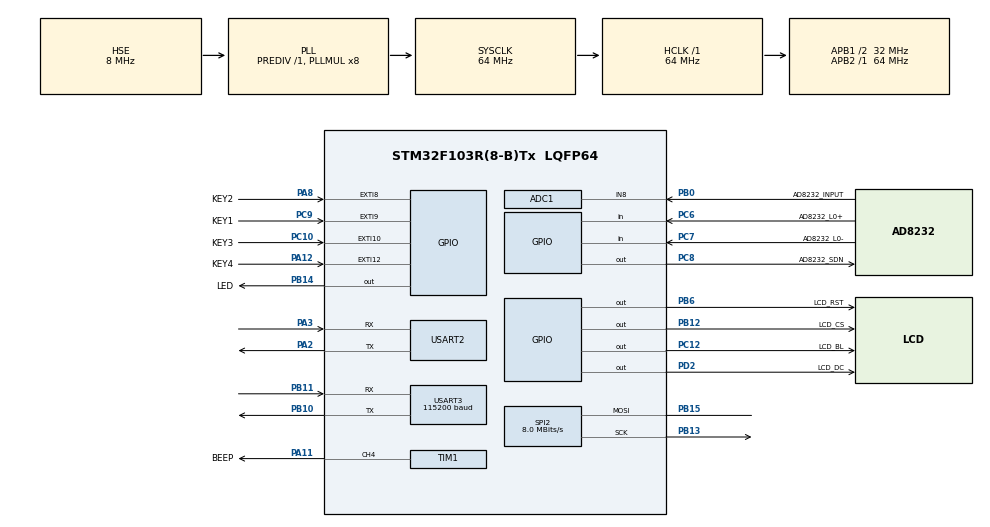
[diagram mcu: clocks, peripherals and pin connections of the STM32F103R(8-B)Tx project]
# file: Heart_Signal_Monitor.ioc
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ADC1.Channel-1\#ChannelRegularConversion=ADC_CHANNEL_8
ADC1.ExternalTrigConv=ADC_EXTERNALTRIGCONV_T3_TRGO
ADC1.NbrOfConversionFlag=1
ADC1.Rank-1\#ChannelRegularConversion=1
ADC1.SamplingTime-1\#ChannelRegularConversion=ADC_SAMPLETIME_55CYCLES_5
ADC1.master=1
Dma.ADC1.0.Direction=DMA_PERIPH_TO_MEMORY
Dma.ADC1.0.Instance=DMA1_Channel1
Dma.ADC1.0.MemDataAlignment=DMA_MDATAALIGN_HALFWORD
Dma.ADC1.0.MemInc=DMA_MINC_ENABLE
Dma.ADC1.0.Mode=DMA_CIRCULAR
Dma.ADC1.0.PeriphDataAlignment=DMA_PDATAALIGN_HALFWORD
Dma.ADC1.0.PeriphInc=DMA_PINC_DISABLE
Dma.ADC1.0.Priority=DMA_PRIORITY_VERY_HIGH
Dma.Request0=ADC1
Mcu.Family=STM32F1
Mcu.Name=STM32F103R(8-B)Tx
Mcu.Package=LQFP64
NVIC.DMA1_Channel1_IRQn=true\:0\:0\:false\:false\:true\:false\:true\:true
NVIC.EXTI15_10_IRQn=true\:0\:0\:false\:false\:true\:true\:true\:true
NVIC.EXTI9_5_IRQn=true\:0\:0\:false\:false\:true\:true\:true\:true
NVIC.PriorityGroup=NVIC_PRIORITYGROUP_4
NVIC.TIM1_BRK_IRQn=true\:0\:0\:false\:false\:true\:true\:true\:true
NVIC.TIM1_CC_IRQn=true\:0\:0\:false\:false\:true\:true\:true\:true
NVIC.TIM1_TRG_COM_IRQn=true\:0\:0\:false\:false\:true\:true\:true\:true
NVIC.TIM1_UP_IRQn=true\:0\:0\:false\:false\:true\:true\:true\:true
NVIC.USART2_IRQn=true\:0\:0\:false\:false\:true\:true\:true\:true
NVIC.USART3_IRQn=true\:0\:0\:false\:false\:true\:true\:true\:true
PA11.GPIO_Label=BEEP
PA11.Signal=S_TIM1_CH4
PA12.GPIO_Label=KEY4
PA12.Signal=GPXTI12
PA13.Mode=Serial_Wire
PA13.Signal=SYS_JTMS-SWDIO
PA14.Mode=Serial_Wire
PA14.Signal=SYS_JTCK-SWCLK
PA2.Mode=Asynchronous
PA2.Signal=USART2_TX
PA3.Mode=Asynchronous
PA3.Signal=USART2_RX
PA8.GPIO_Label=KEY2
PA8.Signal=GPXTI8
PB0.GPIO_Label=AD8232_INPUT
PB0.Signal=ADCx_IN8
PB10.Mode=Asynchronous
PB10.Signal=USART3_TX
PB11.Mode=Asynchronous
PB11.Signal=USART3_RX
PB12.GPIO_Label=LCD_CS
PB12.GPIO_Speed=GPIO_SPEED_FREQ_HIGH
PB12.Signal=GPIO_Output
PB13.Mode=Simplex_Bidirectional_Master
PB13.Signal=SPI2_SCK
PB14.GPIO_Label=LED
PB14.Signal=GPIO_Output
PB15.Mode=Simplex_Bidirectional_Master
PB15.Signal=SPI2_MOSI
PB6.GPIO_Label=LCD_RST
PB6.Signal=GPIO_Output
PC10.GPIO_Label=KEY3
PC10.Signal=GPXTI10
PC12.GPIO_Label=LCD_BL
PC12.Signal=GPIO_Output
PC6.GPIO_Label=AD8232_L0+
PC6.Signal=GPIO_Input
PC7.GPIO_Label=AD8232_L0-
PC7.Signal=GPIO_Input
PC8.GPIO_Label=AD8232_SDN
PC8.GPIO_PuPd=GPIO_PULLUP
PC8.PinState=GPIO_PIN_SET
PC8.Signal=GPIO_Output
PC9.GPIO_Label=KEY1
PC9.Signal=GPXTI9
PD0-OSC_IN.Mode=HSE-External-Clock-Source
PD0-OSC_IN.Signal=RCC_OSC_IN
PD1-OSC_OUT.Mode=HSE-External-Clock-Source
PD1-OSC_OUT.Signal=RCC_OSC_OUT
PD2.GPIO_Label=LCD_DC
PD2.Signal=GPIO_Output
ProjectManager.HeapSize=0x200
ProjectManager.StackSize=0x400
ProjectManager.TargetToolchain=CMake
RCC.ADCPresc=RCC_ADCPCLK2_DIV6
RCC.AHBFreq_Value=64000000
RCC.APB1CLKDivider=RCC_HCLK_DIV2
RCC.APB1Freq_Value=32000000
RCC.APB1TimFreq_Value=64000000
RCC.APB2Freq_Value=64000000
RCC.APB2TimFreq_Value=64000000
RCC.HCLKFreq_Value=64000000
RCC.PLLMUL=RCC_PLL_MUL8
RCC.PLLSourceVirtual=RCC_PLLSOURCE_HSE
RCC.SYSCLKFreq_VALUE=64000000
RCC.SYSCLKSource=RCC_SYSCLKSOURCE_PLLCLK
RCC.USBFreq_Value=64000000
SH.ADCx_IN8.0=ADC2_IN8
SH.ADCx_IN8.1=ADC1_IN8,IN8
SH.S_TIM1_CH4.0=TIM1_CH4,PWM Generation4 CH4
SPI2.BaudRatePrescaler=SPI_BAUDRATEPRESCALER_4
SPI2.CalculateBaudRate=8.0 MBits/s
SPI2.Direction=SPI_DIRECTION_1LINE
SPI2.Mode=SPI_MODE_MASTER
SPI2.VirtualType=VM_MASTER
TIM1.Channel-PWM\ Generation4\ CH4=TIM_CHANNEL_4
TIM3.Period=1999
TIM3.Prescaler=63
TIM3.TIM_MasterOutputTrigger=TIM_TRGO_UPDATE
USART2.VirtualMode=VM_ASYNC
USART3.BaudRate=115200
USART3.VirtualMode=VM_ASYNC
VP_TIM1_VS_ClockSourceINT.Mode=Internal
VP_TIM3_VS_ClockSourceINT.Mode=Internal
board=custom

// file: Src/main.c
/* USER CODE BEGIN Header */
/**
  ******************************************************************************
  * @file           : main.c
  * @brief          : Main program body
  ******************************************************************************
  * @attention
  *
  * Copyright (c) 2026 STMicroelectronics.
  * All rights reserved.
  *
  * This software is licensed under terms that can be found in the LICENSE file
  * in the root directory of this software component.
  * If no LICENSE file comes with this software, it is provided AS-IS.
  *
  ******************************************************************************
  */
/* USER CODE END Header */
#include "main.h"
#include "adc.h"
#include "dma.h"
#include "spi.h"
#include "tim.h"
#include "usart.h"
#include "gpio.h"

/* USER CODE BEGIN Includes */
#include "ecg_app.h"

/* USER CODE END Includes */

void SystemClock_Config(void);

int main(void)
{

  /* MCU Configuration--------------------------------------------------------*/

  /* Reset of all peripherals, Initializes the Flash interface and the Systick. */
  HAL_Init();

  /* Configure the system clock */
  SystemClock_Config();

  /* Initialize all configured peripherals */
  MX_GPIO_Init();
  MX_DMA_Init();
  MX_SPI2_Init();
  MX_TIM1_Init();
  MX_USART2_UART_Init();
  MX_USART3_UART_Init();
  MX_ADC1_Init();
  MX_TIM3_Init();
  /* USER CODE BEGIN 2 */
  ECGApp_Init();

  /* USER CODE END 2 */

  /* Infinite loop */
  /* USER CODE BEGIN WHILE */
  while (1)
  {
    ECGApp_Poll();
    /* USER CODE END WHILE */

  }
}

void SystemClock_Config(void)
{
  RCC_OscInitTypeDef RCC_OscInitStruct = {0};
  RCC_ClkInitTypeDef RCC_ClkInitStruct = {0};
  RCC_PeriphCLKInitTypeDef PeriphClkInit = {0};

  /** Initializes the RCC Oscillators according to the specified parameters
  * in the RCC_OscInitTypeDef structure.
  */
  RCC_OscInitStruct.OscillatorType = RCC_OSCILLATORTYPE_HSE;
  RCC_OscInitStruct.HSEState = RCC_HSE_BYPASS;
  RCC_OscInitStruct.HSEPredivValue = RCC_HSE_PREDIV_DIV1;
  RCC_OscInitStruct.HSIState = RCC_HSI_ON;
  RCC_OscInitStruct.PLL.PLLState = RCC_PLL_ON;
  RCC_OscInitStruct.PLL.PLLSource = RCC_PLLSOURCE_HSE;
  RCC_OscInitStruct.PLL.PLLMUL = RCC_PLL_MUL8;
  if (HAL_RCC_OscConfig(&RCC_OscInitStruct) != HAL_OK)
  {
    Error_Handler();
  }

  /** Initializes the CPU, AHB and APB buses clocks
  */
  RCC_ClkInitStruct.ClockType = RCC_CLOCKTYPE_HCLK|RCC_CLOCKTYPE_SYSCLK
                              |RCC_CLOCKTYPE_PCLK1|RCC_CLOCKTYPE_PCLK2;
  RCC_ClkInitStruct.SYSCLKSource = RCC_SYSCLKSOURCE_PLLCLK;
  RCC_ClkInitStruct.AHBCLKDivider = RCC_SYSCLK_DIV1;
  RCC_ClkInitStruct.APB1CLKDivider = RCC_HCLK_DIV2;
  RCC_ClkInitStruct.APB2CLKDivider = RCC_HCLK_DIV1;

  if (HAL_RCC_ClockConfig(&RCC_ClkInitStruct, FLASH_LATENCY_2) != HAL_OK)
  {
    Error_Handler();
  }
  PeriphClkInit.PeriphClockSelection = RCC_PERIPHCLK_ADC;
  PeriphClkInit.AdcClockSelection = RCC_ADCPCLK2_DIV6;
  if (HAL_RCCEx_PeriphCLKConfig(&PeriphClkInit) != HAL_OK)
  {
    Error_Handler();
  }
}

void Error_Handler(void)
{
  __disable_irq();
  while (1)
  {
  }
}
